# STM32F469xx register map
File version: 1.0
Registers are 32-bit, read-write, reset 0x0 unless marked. A register's access mark holds for its fields unless they carry their own. Offsets are from the block's base; [hi:lo] are bit positions; {n}, {i} and the like mark numbered series; 'fields as' and 'values as' point back to an identical list.

## SYSCFG — System configuration controller
Base 0x40013800
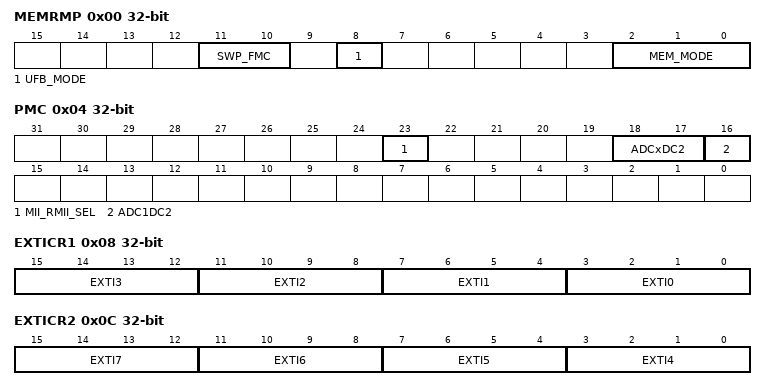
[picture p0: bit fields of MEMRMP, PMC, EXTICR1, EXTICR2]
0x00 MEMRMP — SYSCFG memory remap register
  [11:10] SWP_FMC — FMC memory mapping swap
  [8] UFB_MODE — User Flash Bank mode
    0=BANK1; 1=BANK2
  [2:0] MEM_MODE — SYSCFG_Memory Remap Config
    0=FLASH (Main Flash memory mapped at 0x00000000); 1=SYSTEMFLASH (System Flash memory mapped at 0x00000000); 3=SRAM (SRAM1 mapped at 0x00000000); 2=FMC (FMC(NOR/PSRAM 1 and 2) mapped at 0x00000000)
0x04 PMC — SYSCFG peripheral mode configuration register
  [23] MII_RMII_SEL — Ethernet PHY interface selection
    0=ETHMII (ETH Media MII interface); 1=ETHRMII (ETH Media RMII interface)
  [18:17] ADCxDC2 — Refer to AN4073 on how to use this bit
  [16] ADC1DC2 — Refer to AN4073 on how to use this bit
0x08 EXTICR1 — SYSCFG external interrupt configuration registers
  [4n+3:4n] EXTI{n} (n=0..3) — EXTI {n} configuration
0x0C EXTICR2 — SYSCFG external interrupt configuration registers
  [4n-13:4n-16] EXTI{n} (n=4..7) — EXTI {n} configuration
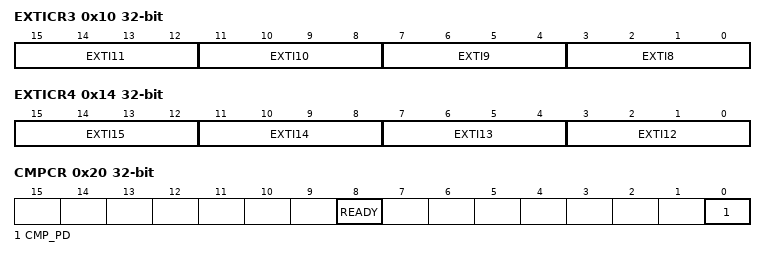
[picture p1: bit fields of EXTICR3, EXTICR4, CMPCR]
0x10 EXTICR3 — SYSCFG external interrupt configuration registers
  [4n-29:4n-32] EXTI{n} (n=8..11) — EXTI {n} configuration
0x14 EXTICR4 — SYSCFG external interrupt configuration registers
  [4n-45:4n-48] EXTI{n} (n=12..15) — EXTI {n} configuration
0x20 CMPCR — SYSCFG Compensation cell control register
  [8] READY — Compensation cell power-down
  [0] CMP_PD — Compensation cell ready flag

## EXTI — External Interrupt/Event Controller
Base 0x40013C00
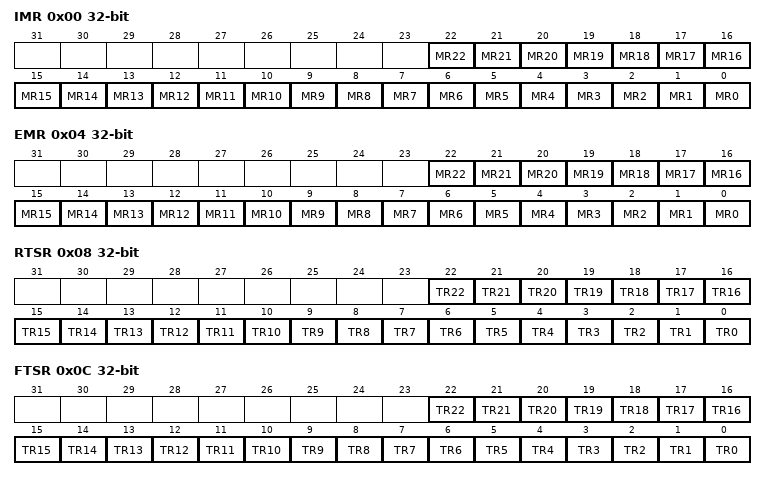
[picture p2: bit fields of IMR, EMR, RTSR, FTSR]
0x00 IMR — EXTI Interrupt mask register
  [n] MR{n} (n=0..22) — Interrupt Mask on line {n}
0x04 EMR — EXTI Event mask register
  [n] MR{n} (n=0..22) — Event Mask on line {n}
0x08 RTSR — EXTI Rising trigger selection register
  [n] TR{n} (n=0..22) — Rising trigger event configuration bit of line {n}
0x0C FTSR — EXTI Falling trigger selection register
  [n] TR{n} (n=0..22) — Falling trigger event configuration bit of line {n}
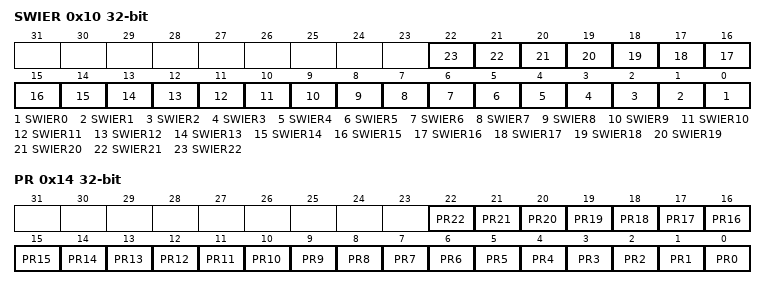
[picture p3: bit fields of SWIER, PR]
0x10 SWIER — EXTI Software interrupt event register
  [n] SWIER{n} (n=0..22) — Software Interrupt on line {n}
0x14 PR — EXTI Pending register
  [n] PR{n} (n=0..22) — Pending bit for line {n}

## SAI1 — Serial Audio Interface
Base 0x40015800
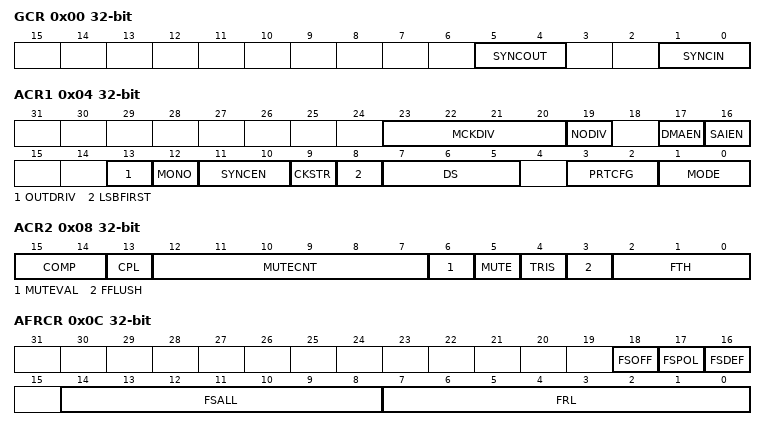
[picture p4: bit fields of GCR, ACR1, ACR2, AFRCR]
0x00 GCR — SAI global configuration register
  [5:4] SYNCOUT — SYNCOUT[1:0] bits (Synchronization Outputs)
  [1:0] SYNCIN — SYNCIN[1:0] bits (Synchronization Inputs)
0x04 ACR1 — SAI block x configuration register 1
  [23:20] MCKDIV — MCKDIV[3:0] (Master ClocK Divider)
  [19] NODIV — No Divider Configuration
  [17] DMAEN — DMA enable
  [16] SAIEN — Audio Block enable
  [13] OUTDRIV — Output Drive
  [12] MONO — Mono mode
  [11:10] SYNCEN — SYNCEN[1:0](SYNChronization ENable)
  [9] CKSTR — ClocK STRobing edge
  [8] LSBFIRST — LSB First Configuration
  [7:5] DS — DS[1:0] bits (Data Size)
  [3:2] PRTCFG — PRTCFG[1:0] bits (Protocol Configuration)
  [1:0] MODE — MODE[1:0] bits (Audio Block Mode)
0x08 ACR2 — SAI block x configuration register 2
  [15:14] COMP — COMP[1:0] (Companding mode)
  [13] CPL — Complement Bit
  [12:7] MUTECNT — MUTECNT[5:0] (MUTE counter)
  [6] MUTEVAL — Muate value
  [5] MUTE — Mute mode
  [4] TRIS — TRIState Management on data line
  [3] FFLUSH — Fifo FLUSH
  [2:0] FTH — FTH[2:0](Fifo THreshold)
0x0C AFRCR — SAI block x frame configuration register
  [18] FSOFF — Frame Synchronization OFFset
  [17] FSPOL — Frame Synchronization POLarity
  [16] FSDEF — Frame Synchronization Definition
  [14:8] FSALL — FRL[6:0] (Frame synchronization active level length)
  [7:0] FRL — FRL[7:0](Frame length)
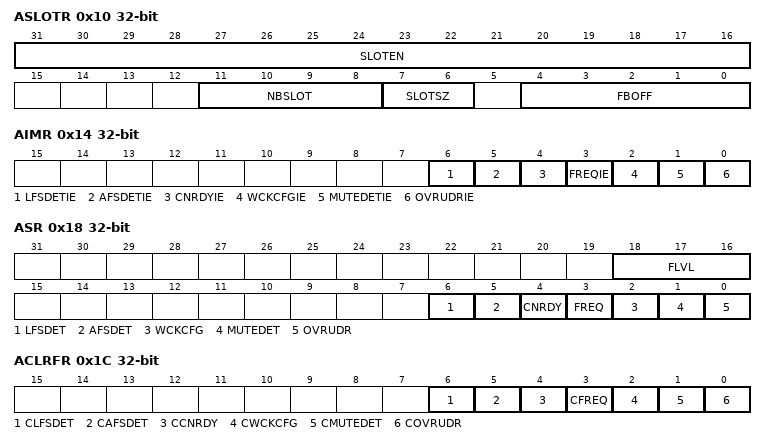
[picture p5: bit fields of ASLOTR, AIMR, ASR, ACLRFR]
0x10 ASLOTR — SAI block x slot register
  [31:16] SLOTEN — SLOTEN[15:0] (Slot Enable)
  [11:8] NBSLOT — NBSLOT[3:0] (Number of Slot in audio Frame)
  [7:6] SLOTSZ — SLOTSZ[1:0] (Slot size)
  [4:0] FBOFF — FRL[4:0](First Bit Offset)
0x14 AIMR — SAI block x interrupt mask register
  [6] LFSDETIE — Late frame synchronization detection interrupt enable
  [5] AFSDETIE — Anticipated frame synchronization detection interrupt enable
  [4] CNRDYIE — Codec not ready interrupt enable
  [3] FREQIE — FIFO request interrupt enable
  [2] WCKCFGIE — Wrong Clock Configuration interrupt enable
  [1] MUTEDETIE — Mute detection interrupt enable
  [0] OVRUDRIE — Overrun underrun interrupt enable
0x18 ASR — SAI block x status register
  [18:16] FLVL — FLVL[2:0] (FIFO Level Threshold)
  [6] LFSDET — Late frame synchronization detection
  [5] AFSDET — Anticipated frame synchronization detection
  [4] CNRDY — Codec not ready
  [3] FREQ — FIFO request
  [2] WCKCFG — Wrong Clock Configuration
  [1] MUTEDET — Mute detection
  [0] OVRUDR — Overrun underrun
0x1C ACLRFR — SAI block x clear flag register
  [6] CLFSDET — Clear Late frame synchronization detection
  [5] CAFSDET — Clear Anticipated frame synchronization detection
  [4] CCNRDY — Clear Codec not ready
  [3] CFREQ — Clear FIFO request
  [2] CWCKCFG — Clear Wrong Clock Configuration
  [1] CMUTEDET — Clear Mute detection
  [0] COVRUDR — Clear Overrun underrun
0x20 ADR — SAI block x data register
  [31:0] DATA
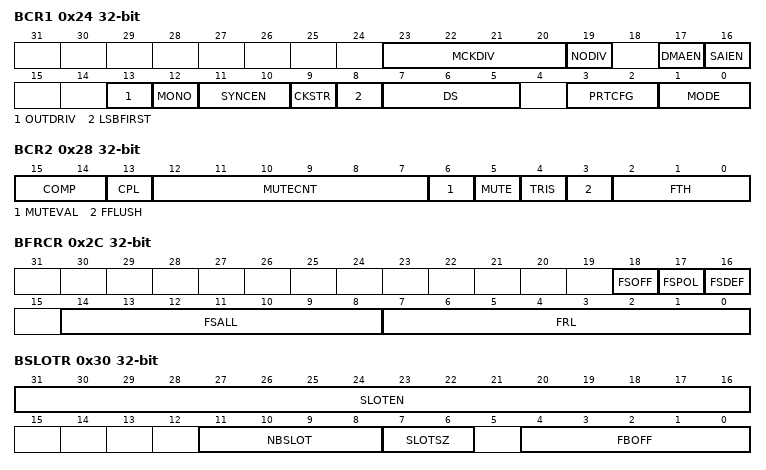
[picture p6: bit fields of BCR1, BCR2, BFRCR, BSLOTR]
0x24 BCR1 — SAI block x configuration register 1
  fields as ACR1
0x28 BCR2 — SAI block x configuration register 2
  fields as ACR2
0x2C BFRCR — SAI block x frame configuration register
  fields as AFRCR
0x30 BSLOTR — SAI block x slot register
  fields as ASLOTR
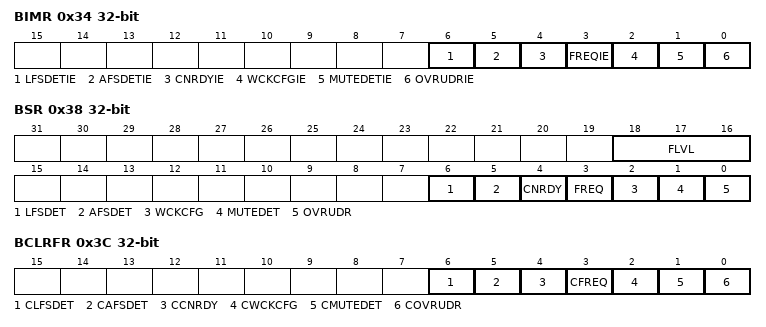
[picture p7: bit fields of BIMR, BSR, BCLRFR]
0x34 BIMR — SAI block x interrupt mask register
  fields as AIMR
0x38 BSR — SAI block x status register
  fields as ASR
0x3C BCLRFR — SAI block x clear flag register
  fields as ACLRFR
0x40 BDR — SAI block x data register
  [31:0] DATA
